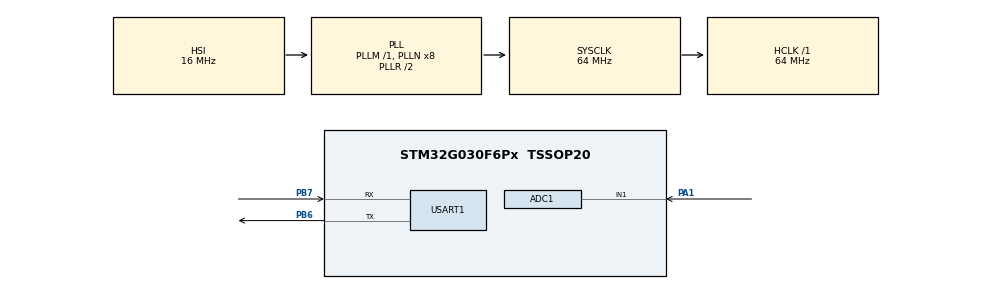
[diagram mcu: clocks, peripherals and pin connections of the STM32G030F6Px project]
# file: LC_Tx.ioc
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ADC1.Channel-2\#ChannelRegularConversion=ADC_CHANNEL_1
ADC1.ContinuousConvMode=ENABLE
ADC1.NbrOfConversionFlag=1
ADC1.Rank-2\#ChannelRegularConversion=1
ADC1.SamplingTime-2\#ChannelRegularConversion=ADC_SAMPLINGTIME_COMMON_1
ADC1.SelectedChannel=ADC_CHANNEL_1
ADC1.master=1
Dma.Request0=USART1_TX
Dma.Request1=USART1_RX
Dma.USART1_RX.1.Direction=DMA_PERIPH_TO_MEMORY
Dma.USART1_RX.1.EventEnable=DISABLE
Dma.USART1_RX.1.Instance=DMA1_Channel2
Dma.USART1_RX.1.MemDataAlignment=DMA_MDATAALIGN_WORD
Dma.USART1_RX.1.MemInc=DMA_MINC_ENABLE
Dma.USART1_RX.1.Mode=DMA_NORMAL
Dma.USART1_RX.1.PeriphDataAlignment=DMA_PDATAALIGN_WORD
Dma.USART1_RX.1.PeriphInc=DMA_PINC_DISABLE
Dma.USART1_RX.1.Polarity=HAL_DMAMUX_REQ_GEN_RISING
Dma.USART1_RX.1.Priority=DMA_PRIORITY_LOW
Dma.USART1_RX.1.RequestNumber=1
Dma.USART1_RX.1.SignalID=NONE
Dma.USART1_RX.1.SyncEnable=DISABLE
Dma.USART1_RX.1.SyncPolarity=HAL_DMAMUX_SYNC_NO_EVENT
Dma.USART1_RX.1.SyncRequestNumber=1
Dma.USART1_RX.1.SyncSignalID=NONE
Dma.USART1_TX.0.Direction=DMA_MEMORY_TO_PERIPH
Dma.USART1_TX.0.EventEnable=DISABLE
Dma.USART1_TX.0.Instance=DMA1_Channel1
Dma.USART1_TX.0.MemDataAlignment=DMA_MDATAALIGN_BYTE
Dma.USART1_TX.0.MemInc=DMA_MINC_ENABLE
Dma.USART1_TX.0.Mode=DMA_NORMAL
Dma.USART1_TX.0.PeriphDataAlignment=DMA_PDATAALIGN_BYTE
Dma.USART1_TX.0.PeriphInc=DMA_PINC_DISABLE
Dma.USART1_TX.0.Polarity=HAL_DMAMUX_REQ_GEN_RISING
Dma.USART1_TX.0.Priority=DMA_PRIORITY_LOW
Dma.USART1_TX.0.RequestNumber=1
Dma.USART1_TX.0.SignalID=NONE
Dma.USART1_TX.0.SyncEnable=DISABLE
Dma.USART1_TX.0.SyncPolarity=HAL_DMAMUX_SYNC_NO_EVENT
Dma.USART1_TX.0.SyncRequestNumber=1
Dma.USART1_TX.0.SyncSignalID=NONE
Mcu.Family=STM32G0
Mcu.Name=STM32G030F6Px
Mcu.Package=TSSOP20
NVIC.DMA1_Channel1_IRQn=true\:0\:0\:false\:false\:true\:false\:true\:true
NVIC.DMA1_Channel2_3_IRQn=true\:0\:0\:false\:false\:true\:false\:true\:true
NVIC.TIM3_IRQn=true\:0\:0\:false\:false\:true\:true\:true\:true
NVIC.USART1_IRQn=true\:0\:0\:false\:false\:true\:true\:true\:true
PA1.Mode=IN1
PA1.Signal=ADC1_IN1
PA13.Mode=Serial_Wire
PA13.Signal=SYS_SWDIO
PA14-BOOT0.Mode=Serial_Wire
PA14-BOOT0.Signal=SYS_SWCLK
PA14-BOOT0__PA15.StandardMode=true
PB0__PB1__PB2__PA8.StandardMode=true
PB3__PB4__PB5__PB6.StandardMode=true
PB6.Mode=Asynchronous
PB6.Signal=USART1_TX
PB7.Mode=Asynchronous
PB7.Signal=USART1_RX
PB7__PB8.StandardMode=true
PC14-OSC32_IN\ (PC14)__PB9.StandardMode=true
ProjectManager.HeapSize=0x200
ProjectManager.StackSize=0x400
ProjectManager.TargetToolchain=STM32CubeIDE
RCC.ADCFreq_Value=64000000
RCC.AHBFreq_Value=64000000
RCC.CortexFreq_Value=64000000
RCC.EXTERNAL_CLOCK_VALUE=12288000
RCC.HCLKFreq_Value=64000000
RCC.HSE_VALUE=8000000
RCC.HSI_VALUE=16000000
RCC.LSE_VALUE=32768
RCC.SYSCLKFreq_VALUE=64000000
RCC.SYSCLKSource=RCC_SYSCLKSOURCE_PLLCLK
RCC.VCOOutputFreq_Value=128000000
TIM3.AutoReloadPreload=TIM_AUTORELOAD_PRELOAD_ENABLE
TIM3.Period=9
TIM3.Prescaler=6399
USART1.VirtualMode-Asynchronous=VM_ASYNC
VP_TIM3_VS_ClockSourceINT.Mode=Internal
board=custom

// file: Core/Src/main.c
/* USER CODE BEGIN Header */
/**
  ******************************************************************************
  * @file           : main.c
  * @brief          : Main program body
  ******************************************************************************
  * @attention
  *
  * Copyright (c) 2023 STMicroelectronics.
  * All rights reserved.
  *
  * This software is licensed under terms that can be found in the LICENSE file
  * in the root directory of this software component.
  * If no LICENSE file comes with this software, it is provided AS-IS.
  *
  ******************************************************************************
  */
/* USER CODE END Header */
#include "main.h"
#include "adc.h"
#include "dma.h"
#include "tim.h"
#include "usart.h"
#include "gpio.h"

void SystemClock_Config(void);

/* USER CODE BEGIN 0 */
uint32_t value_adc=0;
uint8_t data[2];
uint32_t val_cnt=1;
uint32_t values[200]={0};
void HAL_TIM_PeriodElapsedCallback(TIM_HandleTypeDef *htim)
{
	if(htim->Instance==TIM3)
	{
		HAL_ADC_PollForConversion(&hadc1, HAL_MAX_DELAY);
		value_adc = HAL_ADC_GetValue(&hadc1);
		HAL_UART_Transmit_DMA(&huart1,(uint8_t*)&value_adc,sizeof(uint32_t));
//		values[val_cnt]=value_adc;
//		//HAL_UART_Transmit(&huart1,(uint8_t*)&value_adc,sizeof(uint32_t),10);
//		val_cnt++;
//		if(val_cnt==200)
//		{
//			val_cnt=0;
//			usartSend((uint8_t *)values,200*sizeof(uint32_t));
//			memset(values,0,sizeof(values));
//
//		}
	}
}
/* USER CODE END 0 */

int main(void)
{

  /* MCU Configuration--------------------------------------------------------*/

  /* Reset of all peripherals, Initializes the Flash interface and the Systick. */
  HAL_Init();

  /* Configure the system clock */
  SystemClock_Config();

  /* Initialize all configured peripherals */
  MX_GPIO_Init();
  MX_DMA_Init();
  MX_ADC1_Init();
  MX_USART1_UART_Init();
  MX_TIM3_Init();
  /* USER CODE BEGIN 2 */
  HAL_ADCEx_Calibration_Start(&hadc1);
  HAL_ADC_Start(&hadc1);
  HAL_TIM_Base_Start_IT(&htim3);
  /* USER CODE END 2 */

  /* Infinite loop */
  while (1)
  {

    /* USER CODE BEGIN 3 */
//	  uint8_t Test[] = "Hello World !!!\r\n"; //Data to send
//	  HAL_UART_Transmit(&huart1,Test,sizeof(Test),10);// Sending in normal mode
//	  HAL_Delay(500);

	  //HAL_ADC_PollForConversion(&hadc1, HAL_MAX_DELAY);
	  //value_adc = HAL_ADC_GetValue(&hadc1);
	  //HAL_UART_Transmit(&huart1,(uint8_t*)&value_adc,sizeof(uint32_t),10);
	  //HAL_Delay(5);
	  //HAL_UART_Transmit_DMA(&huart1,test,sizeof(test)-1);
	  //HAL_UART_DMAStop(&huart1);
	  //HAL_Delay(500);
  }
  /* USER CODE END 3 */
}

void SystemClock_Config(void)
{
  RCC_OscInitTypeDef RCC_OscInitStruct = {0};
  RCC_ClkInitTypeDef RCC_ClkInitStruct = {0};

  /** Configure the main internal regulator output voltage
  */
  HAL_PWREx_ControlVoltageScaling(PWR_REGULATOR_VOLTAGE_SCALE1);

  /** Initializes the RCC Oscillators according to the specified parameters
  * in the RCC_OscInitTypeDef structure.
  */
  RCC_OscInitStruct.OscillatorType = RCC_OSCILLATORTYPE_HSI;
  RCC_OscInitStruct.HSIState = RCC_HSI_ON;
  RCC_OscInitStruct.HSIDiv = RCC_HSI_DIV1;
  RCC_OscInitStruct.HSICalibrationValue = RCC_HSICALIBRATION_DEFAULT;
  RCC_OscInitStruct.PLL.PLLState = RCC_PLL_ON;
  RCC_OscInitStruct.PLL.PLLSource = RCC_PLLSOURCE_HSI;
  RCC_OscInitStruct.PLL.PLLM = RCC_PLLM_DIV1;
  RCC_OscInitStruct.PLL.PLLN = 8;
  RCC_OscInitStruct.PLL.PLLP = RCC_PLLP_DIV2;
  RCC_OscInitStruct.PLL.PLLR = RCC_PLLR_DIV2;
  if (HAL_RCC_OscConfig(&RCC_OscInitStruct) != HAL_OK)
  {
    Error_Handler();
  }

  /** Initializes the CPU, AHB and APB buses clocks
  */
  RCC_ClkInitStruct.ClockType = RCC_CLOCKTYPE_HCLK|RCC_CLOCKTYPE_SYSCLK
                              |RCC_CLOCKTYPE_PCLK1;
  RCC_ClkInitStruct.SYSCLKSource = RCC_SYSCLKSOURCE_PLLCLK;
  RCC_ClkInitStruct.AHBCLKDivider = RCC_SYSCLK_DIV1;
  RCC_ClkInitStruct.APB1CLKDivider = RCC_HCLK_DIV1;

  if (HAL_RCC_ClockConfig(&RCC_ClkInitStruct, FLASH_LATENCY_2) != HAL_OK)
  {
    Error_Handler();
  }
}

void Error_Handler(void)
{
  __disable_irq();
  while (1)
  {
  }
}
